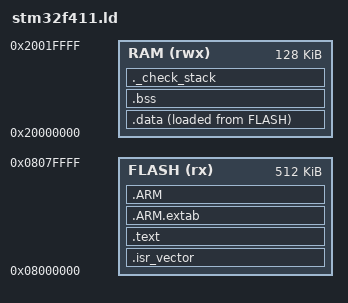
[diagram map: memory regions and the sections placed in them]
/*
 * Linker script for STM32F411CEU6.
 * 512 KB flash @ 0x08000000, 128 KB SRAM @ 0x20000000.
 */

ENTRY(Reset_Handler)

MEMORY
{
    FLASH (rx)  : ORIGIN = 0x08000000, LENGTH = 512K
    RAM   (rwx) : ORIGIN = 0x20000000, LENGTH = 128K
}

_estack = ORIGIN(RAM) + LENGTH(RAM);

SECTIONS
{
    .isr_vector :
    {
        KEEP(*(.isr_vector))
    } > FLASH

    .text :
    {
        *(.text*)
        *(.rodata*)
        *(.glue_7)
        *(.glue_7t)
        KEEP(*(.init))
        KEEP(*(.fini))
        . = ALIGN(4);
        _etext = .;
    } > FLASH

    .ARM.extab   : { *(.ARM.extab* .gnu.linkonce.armextab.*) } > FLASH
    .ARM         : { *(.ARM.exidx*) } > FLASH

    _sidata = LOADADDR(.data);

    .data :
    {
        . = ALIGN(4);
        _sdata = .;
        *(.data*)
        . = ALIGN(4);
        _edata = .;
    } > RAM AT > FLASH

    .bss :
    {
        . = ALIGN(4);
        _sbss = .;
        *(.bss*)
        *(COMMON)
        . = ALIGN(4);
        _ebss = .;
    } > RAM

    /* Ensure we didn't overflow SRAM. */
    ._check_stack :
    {
        . = ALIGN(8);
        . = . + 2048;   /* minimum stack we insist on */
    } > RAM

    /DISCARD/ : { *(.ARM.attributes) }
}
